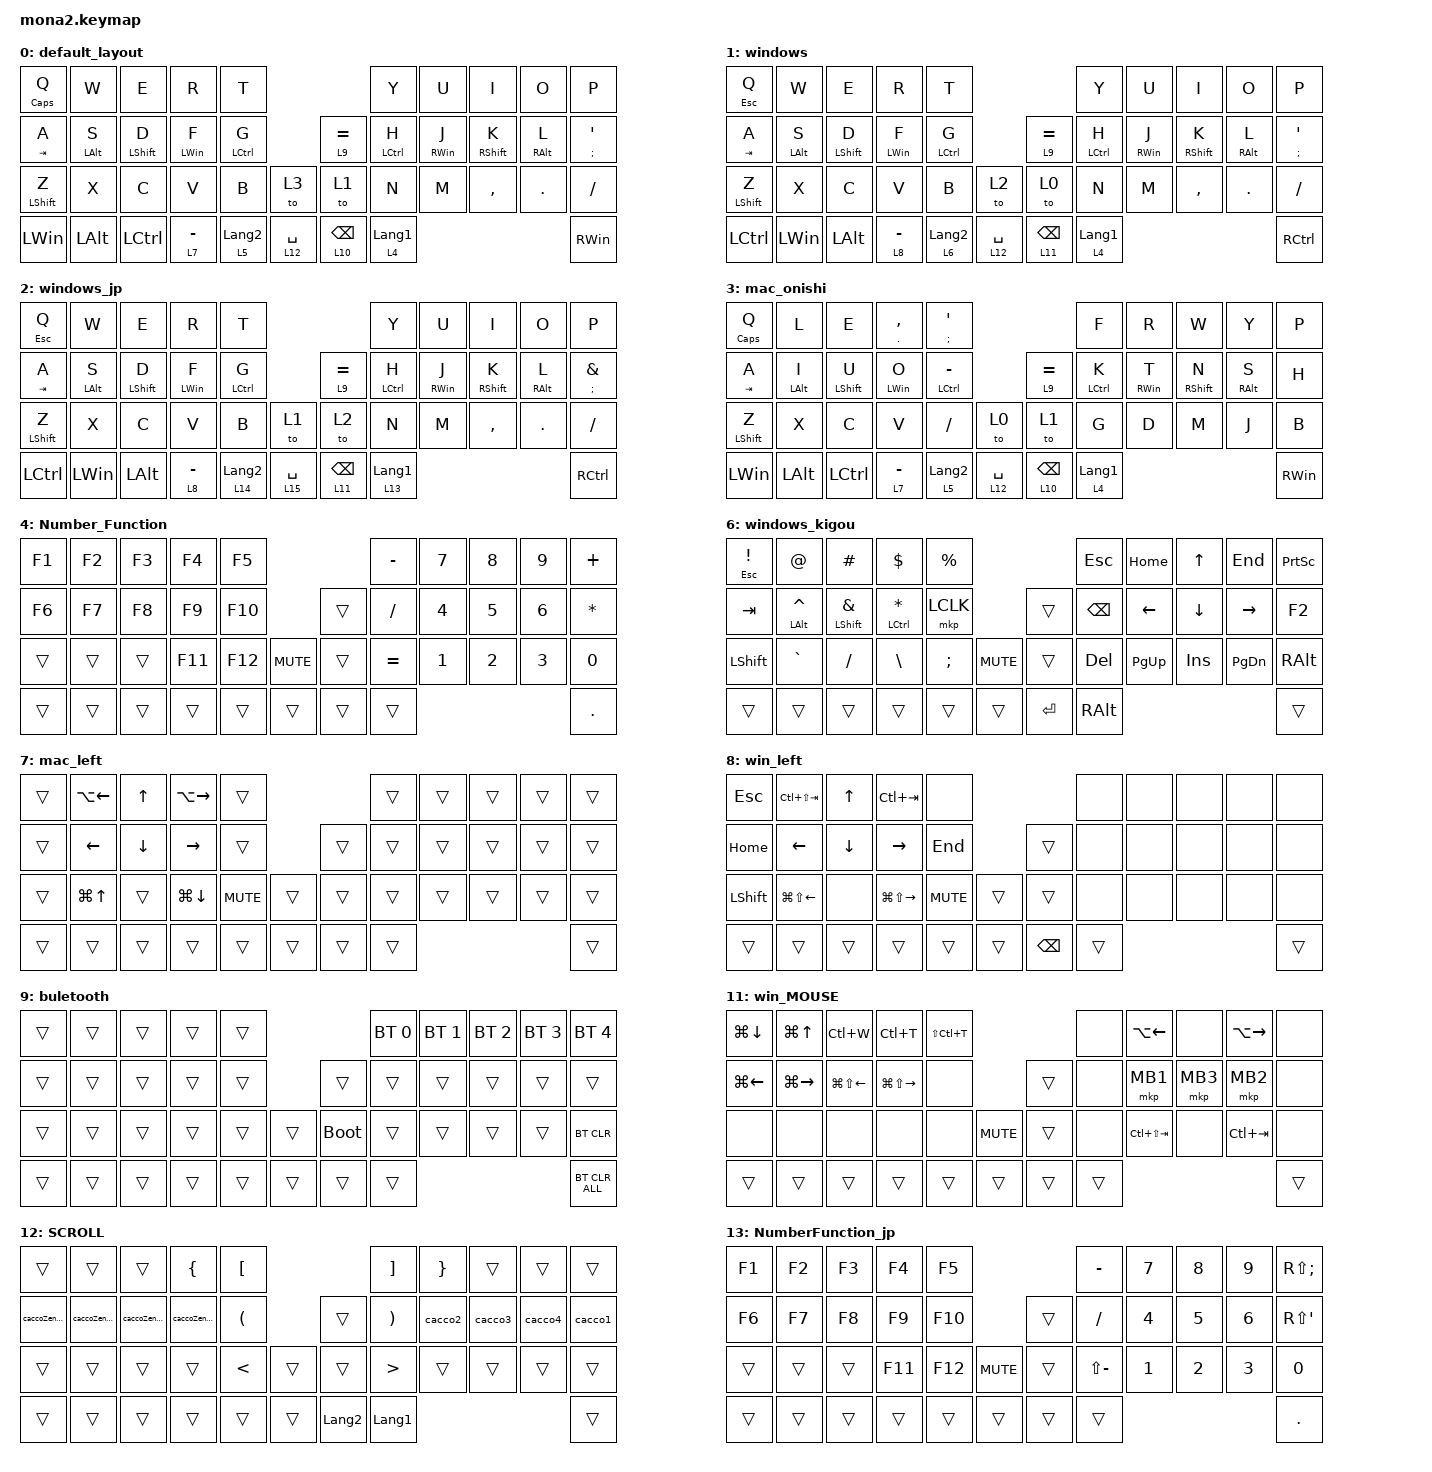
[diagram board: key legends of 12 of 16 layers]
#include <input/processors.dtsi>
#include <dt-bindings/zmk/input_transform.h>
#include <zephyr/dt-bindings/input/input-event-codes.h>
#include <behaviors.dtsi>
#include <dt-bindings/zmk/bt.h>
#include <dt-bindings/zmk/keys.h>
#include <dt-bindings/zmk/pointing.h>

#define ZMK_POINTING_DEFAULT_SCRL_VAL 100
#define MOUSE 5
#define SCROLL 12

&mt {
    flavor = "balanced";
    quick-tap-ms = <0>;
};

&lt {
    quick-tap-ms = <300>;
    flavor = "balanced";
};

/ {
    combos {
        compatible = "zmk,combos";

        layer4_ESC {
            bindings = <&lt 5 ESC>;
            key-positions = <39 38>;
        };

        tab {
            bindings = <&kp TAB>;
            key-positions = <11 12>;
        };
    };

    macros {
        to_layer_0: to_layer_0 {
            compatible = "zmk,behavior-macro-one-param";
            #binding-cells = <1>;
            bindings = <&to 1 &macro_param_1to1 &kp MACRO_PLACEHOLDER>;
            label = "TO_LAYER_0";
        };

        cacco1: cacco1 {
            compatible = "zmk,behavior-macro";
            #binding-cells = <0>;
            bindings = <&kp LANGUAGE_1 &kp LEFT_BRACE &kp RIGHT_BRACE &kp RET &kp LEFT_ARROW>;
            label = "CACCO1";
        };

        cacco2: cacco2 {
            compatible = "zmk,behavior-macro";
            #binding-cells = <0>;
            bindings = <&kp LANGUAGE_1 &kp LEFT_PARENTHESIS &kp RIGHT_PARENTHESIS &kp RETURN &kp LEFT>;
            label = "CACCO2";
        };

        cacco3: cacco3 {
            compatible = "zmk,behavior-macro";
            #binding-cells = <0>;
            bindings = <&kp LANGUAGE_1 &kp LEFT_BRACKET &kp RIGHT_BRACKET &kp RET &kp LEFT>;
            label = "CACCO3";
        };

        cacco4: cacco4 {
            compatible = "zmk,behavior-macro";
            #binding-cells = <0>;
            bindings = <&kp LANGUAGE_1 &kp LESS_THAN &kp GREATER_THAN &kp RET &kp LEFT_ARROW>;
            label = "CACCO4";
        };

        caccoZenkaku1: caccoZenkaku1 {
            compatible = "zmk,behavior-macro";
            #binding-cells = <0>;
            bindings = <&kp LANGUAGE_2 &kp LEFT_BRACE &kp RIGHT_BRACE &kp LEFT>;
            label = "CACCOZENKAKU1";
        };

        caccoZenkaku2: caccoZenkaku2 {
            compatible = "zmk,behavior-macro";
            #binding-cells = <0>;
            bindings = <&kp LANGUAGE_2 &kp LEFT_PARENTHESIS &kp RIGHT_PARENTHESIS &kp LEFT_ARROW>;
            label = "CACCOZENKAKU2";
        };

        caccoZenkaku3: caccoZenkaku3 {
            compatible = "zmk,behavior-macro";
            #binding-cells = <0>;
            bindings = <&kp LANGUAGE_2 &kp LEFT_BRACKET &kp RIGHT_BRACKET &kp LEFT>;
            label = "CACCOZENKAKU3";
        };

        caccoZenkaku4: caccoZenkaku4 {
            compatible = "zmk,behavior-macro";
            #binding-cells = <0>;
            bindings = <&kp LANGUAGE_2 &kp LESS_THAN &kp GREATER_THAN &kp LEFT>;
            label = "CACCOZENKAKU4";
        };

        cacco1JpHankaku: cacco1JpHankaku {
            compatible = "zmk,behavior-macro";
            #binding-cells = <0>;
            bindings = <&kp LANGUAGE_2 &kp RIGHT_BRACE &kp LS(BACKSLASH) &kp LEFT_ARROW>;
            label = "CACCO1JPHANKAKU";
        };

        cacco2JpHankaku: cacco2JpHankaku {
            compatible = "zmk,behavior-macro";
            #binding-cells = <0>;
            bindings = <&kp LANGUAGE_2 &kp ASTERISK &kp LEFT_PARENTHESIS &kp LEFT>;
            label = "CACCO2JPHANKAKU";
        };

        cacco3JpHankaku: cacco3JpHankaku {
            compatible = "zmk,behavior-macro";
            #binding-cells = <0>;
            bindings = <&kp LANGUAGE_2 &kp RIGHT_BRACKET &kp BACKSLASH &kp LEFT>;
            label = "CACCO3JPHANKAKU";
        };

        cacco4JpHankaku: cacco4JpHankaku {
            compatible = "zmk,behavior-macro";
            #binding-cells = <0>;
            bindings = <&kp LANGUAGE_2 &kp LESS_THAN &kp GREATER_THAN &kp LEFT>;
            label = "CACCO4JPHANKAKU";
        };

        cacco1JpZenkaku: cacco1JpZenkaku {
            compatible = "zmk,behavior-macro";
            #binding-cells = <0>;
            bindings = <&kp LANGUAGE_1 &kp RIGHT_BRACE &kp LS(BACKSLASH) &kp ENTER &kp LEFT>;
            label = "CACCO1JPZENKAKU";
        };

        cacco2JpZenkaku: cacco2JpZenkaku {
            compatible = "zmk,behavior-macro";
            #binding-cells = <0>;
            bindings = <&kp LANGUAGE_1 &kp ASTERISK &kp LEFT_PARENTHESIS &kp ENTER &kp LEFT_ARROW>;
            label = "CACCO2JPZENKAKU";
        };

        cacco3JpZenkaku: cacco3JpZenkaku {
            compatible = "zmk,behavior-macro";
            #binding-cells = <0>;
            bindings = <&kp LANGUAGE_1 &kp RIGHT_BRACKET &kp BACKSLASH &kp ENTER &kp LEFT>;
            label = "CACCO3JPZENKAKU";
        };

        cacco4JpZenkaku: cacco4JpZenkaku {
            compatible = "zmk,behavior-macro";
            #binding-cells = <0>;
            bindings = <&kp LANGUAGE_1 &kp LESS_THAN &kp GREATER_THAN &kp ENTER &kp LEFT>;
            label = "CACCO4JPZENKAKU";
        };

        jp_underbar: jp_underbar {
            compatible = "zmk,behavior-macro";
            #binding-cells = <0>;
            bindings =
                <&kp LANGUAGE_1 &kp L &kp I &kp A &kp ENTER>,
                <&macro_wait_time 1>,
                <&kp TAB>,
                <&macro_wait_time 1>,
                <&kp ENTER &kp LANGUAGE_2>;

            label = "JP_UNDERBAR";
            wait-ms = <5>;
        };

        jp_pipe: jp_pipe {
            compatible = "zmk,behavior-macro";
            #binding-cells = <0>;
            bindings =
                <&kp LANGUAGE_1 &kp L &kp A &kp I>,
                <&macro_wait_time 1>,
                <&kp TAB>,
                <&macro_wait_time 1>,
                <&kp ENTER &kp LANGUAGE_2>;

            label = "JP_PIPE";
            wait-ms = <5>;
        };

        jp_en: jp_en {
            compatible = "zmk,behavior-macro";
            #binding-cells = <0>;
            bindings =
                <&kp LANG_HANGEUL &kp L &kp U &kp A>,
                <&macro_wait_time 1>,
                <&kp TAB>,
                <&macro_wait_time 1>,
                <&kp ENTER &kp LANGUAGE_2>;

            label = "JP_EN";
            wait-ms = <5>;
        };
    };

    behaviors {
        lt_to_layer_0: lt_to_layer_0 {
            compatible = "zmk,behavior-hold-tap";
            label = "LAYER_TAP_TO_0";
            bindings = <&mo>, <&to_layer_0>;

            #binding-cells = <2>;
            tapping-term-ms = <200>;
        };

        scroll_up_down: mouse_wheel_up_down {
            compatible = "zmk,behavior-sensor-rotate";
            #sensor-binding-cells = <0>;
            bindings = <&msc SCRL_DOWN>, <&msc SCRL_UP>;

            tap-ms = <20>;
        };

        scroll_right_left: mouse_wheel_right_left {
            compatible = "zmk,behavior-sensor-rotate";
            #sensor-binding-cells = <0>;
            bindings = <&msc SCRL_LEFT>, <&msc SCRL_RIGHT>;

            tap-ms = <20>;
        };
    };

    keymap {
        compatible = "zmk,keymap";

        default_layout {
            bindings = <
&mt CAPSLOCK Q    &kp W           &kp E             &kp R           &kp T                                               &kp Y             &kp U            &kp I              &kp O            &kp P
&mt TAB A         &mt LEFT_ALT S  &mt LEFT_SHIFT D  &mt LEFT_WIN F  &mt LCTRL G                       &lt 9 EQUAL       &mt LCTRL H       &mt RIGHT_WIN J  &mt RIGHT_SHIFT K  &mt RIGHT_ALT L  &mt SEMICOLON SQT
&mt LEFT_SHIFT Z  &kp X           &kp C             &kp V           &kp B             &to 3           &to 1             &kp N             &kp M            &kp COMMA          &kp DOT          &kp SLASH
&kp LEFT_WIN      &kp LEFT_ALT    &kp LCTRL         &lt 7 MINUS     &lt 5 LANGUAGE_2  &lt 12 SPACE    &lt 10 BACKSPACE  &lt 4 LANGUAGE_1                                                       &kp RIGHT_WIN
            >;

            sensor-bindings = <&scroll_up_down>;
        };

        windows {
            bindings = <
&mt ESCAPE Q      &kp W           &kp E             &kp R           &kp T                                               &kp Y             &kp U            &kp I              &kp O            &kp P
&mt TAB A         &mt LEFT_ALT S  &mt LEFT_SHIFT D  &mt LEFT_WIN F  &mt LCTRL G                       &lt 9 EQUAL       &mt LCTRL H       &mt RIGHT_WIN J  &mt RIGHT_SHIFT K  &mt RIGHT_ALT L  &mt SEMICOLON SQT
&mt LEFT_SHIFT Z  &kp X           &kp C             &kp V           &kp B             &to 2           &to 0             &kp N             &kp M            &kp COMMA          &kp DOT          &kp SLASH
&kp LCTRL         &kp LEFT_WIN    &kp LEFT_ALT      &lt 8 MINUS     &lt 6 LANGUAGE_2  &lt 12 SPACE    &lt 11 BACKSPACE  &lt 4 LANGUAGE_1                                                       &kp RCTRL
            >;

            sensor-bindings = <&scroll_up_down>;
        };

        windows_jp {
            bindings = <
&mt ESCAPE Q      &kp W           &kp E             &kp R           &kp T                                                &kp Y              &kp U            &kp I              &kp O            &kp P
&mt TAB A         &mt LEFT_ALT S  &mt LEFT_SHIFT D  &mt LEFT_WIN F  &mt LCTRL G                        &lt 9 EQUAL       &mt LCTRL H        &mt RIGHT_WIN J  &mt RIGHT_SHIFT K  &mt RIGHT_ALT L  &mt SEMICOLON AMPERSAND
&mt LEFT_SHIFT Z  &kp X           &kp C             &kp V           &kp B              &to 1           &to 2             &kp N              &kp M            &kp COMMA          &kp DOT          &kp SLASH
&kp LCTRL         &kp LEFT_WIN    &kp LEFT_ALT      &lt 8 MINUS     &lt 14 LANGUAGE_2  &lt 15 SPACE    &lt 11 BACKSPACE  &lt 13 LANGUAGE_1                                                       &kp RCTRL
            >;

            sensor-bindings = <&scroll_up_down>;
        };

        mac_onishi {
            bindings = <
&mt CAPS Q        &kp L           &kp E             &mt PERIOD COMMA  &mt SEMICOLON SQT                                    &kp F             &kp R            &kp W              &kp Y            &kp P
&mt TAB A         &mt LEFT_ALT I  &mt LEFT_SHIFT U  &mt LEFT_WIN O    &mt LCTRL MINUS                    &lt 9 EQUAL       &mt LCTRL K       &mt RIGHT_WIN T  &mt RIGHT_SHIFT N  &mt RIGHT_ALT S  &kp H
&mt LEFT_SHIFT Z  &kp X           &kp C             &kp V             &kp SLASH          &to 0           &to 1             &kp G             &kp D            &kp M              &kp J            &kp B
&kp LEFT_WIN      &kp LEFT_ALT    &kp LCTRL         &lt 7 MINUS       &lt 5 LANGUAGE_2   &lt 12 SPACE    &lt 10 BACKSPACE  &lt 4 LANGUAGE_1                                                       &kp RIGHT_WIN
            >;

            sensor-bindings = <&scroll_up_down>;
        };

        Number_Function {
            bindings = <
&kp F1  &kp F2  &kp F3  &kp F4   &kp F5                         &kp MINUS  &kp N7        &kp N8        &kp N9        &kp PLUS
&kp F6  &kp F7  &kp F8  &kp F9   &kp F10                &trans  &kp SLASH  &kp NUMBER_4  &kp N5        &kp NUMBER_6  &kp ASTERISK
&trans  &trans  &trans  &kp F11  &kp F12  &kp C_MUTE    &trans  &kp EQUAL  &kp NUMBER_1  &kp NUMBER_2  &kp NUMBER_3  &kp N0
&trans  &trans  &trans  &trans   &trans   &trans        &trans  &trans                                               &kp PERIOD
            >;

            sensor-bindings = <&inc_dec_kp C_VOLUME_DOWN C_VOLUME_UP>;
        };

        mac_kigou {
            bindings = <
&mt ESCAPE EXCLAMATION  &kp AT_SIGN         &kp HASH                  &kp DOLLAR          &kp PERCENT                              &kp ESCAPE     &kp LG(LEFT)      &kp UP_ARROW  &kp LG(RIGHT)  &kp LC(LS(LG(NUMBER_4)))
&kp TAB                 &mt LEFT_ALT CARET  &mt LEFT_SHIFT AMPERSAND  &mt LCTRL ASTERISK  &mkp LCLK                    &trans      &kp BACKSPACE  &kp LEFT_ARROW    &kp DOWN      &kp RIGHT      &kp LC(U)
&kp LSHIFT              &kp GRAVE           &kp SLASH                 &kp BACKSLASH       &kp SEMICOLON  &kp C_MUTE    &trans      &kp DELETE     &kp LG(UP_ARROW)  &kp INS       &kp LG(DOWN)   &kp RIGHT_ALT
&trans                  &trans              &trans                    &trans              &trans         &trans        &kp RETURN  &kp RIGHT_ALT                                                 &kp LS(LG(NUMBER_3))
            >;

            sensor-bindings = <&inc_dec_kp F14 F15>;
        };

        windows_kigou {
            bindings = <
&mt ESCAPE EXCLAMATION  &kp AT_SIGN         &kp HASH                  &kp DOLLAR          &kp PERCENT                              &kp ESCAPE     &kp HOME        &kp UP_ARROW  &kp END        &kp PRINTSCREEN
&kp TAB                 &mt LEFT_ALT CARET  &mt LEFT_SHIFT AMPERSAND  &mt LCTRL ASTERISK  &mkp LCLK                    &trans      &kp BACKSPACE  &kp LEFT_ARROW  &kp DOWN      &kp RIGHT      &kp F2
&kp LSHIFT              &kp GRAVE           &kp SLASH                 &kp BACKSLASH       &kp SEMICOLON  &kp C_MUTE    &trans      &kp DELETE     &kp PAGE_UP     &kp INS       &kp PAGE_DOWN  &kp RIGHT_ALT
&trans                  &trans              &trans                    &trans              &trans         &trans        &kp RETURN  &kp RIGHT_ALT                                               &trans
            >;

            sensor-bindings = <&inc_dec_kp PAGE_DOWN PAGE_UP>;
        };

        mac_left {
            bindings = <
&trans  &kp LA(LEFT_ARROW)  &kp UP_ARROW  &kp LA(RIGHT)  &trans                        &trans  &trans  &trans  &trans  &trans
&trans  &kp LEFT_ARROW      &kp DOWN      &kp RIGHT      &trans                &trans  &trans  &trans  &trans  &trans  &trans
&trans  &kp LG(UP_ARROW)    &trans        &kp LG(DOWN)   &kp C_MUTE  &trans    &trans  &trans  &trans  &trans  &trans  &trans
&trans  &trans              &trans        &trans         &trans      &trans    &trans  &trans                          &trans
            >;

            sensor-bindings = <&inc_dec_kp F15 F14>;
        };

        win_left {
            bindings = <
&kp ESCAPE      &kp LC(LS(TAB))         &kp UP_ARROW    &kp LC(TAB)              &none                                &none   &none  &none  &none  &none
&kp HOME        &kp LEFT_ARROW          &kp DOWN_ARROW  &kp RIGHT_ARROW          &kp END               &trans         &none   &none  &none  &none  &none
&kp LEFT_SHIFT  &kp LG(LS(LEFT_ARROW))  &none           &kp LG(LS(RIGHT_ARROW))  &kp C_MUTE  &trans    &trans         &none   &none  &none  &none  &none
&trans          &trans                  &trans          &trans                   &trans      &trans    &kp BACKSPACE  &trans                       &trans
            >;

            sensor-bindings = <&inc_dec_kp C_VOLUME_DOWN C_VOLUME_UP>;
        };

        buletooth {
            bindings = <
&trans  &trans  &trans  &trans  &trans                         &bt BT_SEL 0  &bt BT_SEL 1  &bt BT_SEL 2  &bt BT_SEL 3  &bt BT_SEL 4
&trans  &trans  &trans  &trans  &trans            &trans       &trans        &trans        &trans        &trans        &trans
&trans  &trans  &trans  &trans  &trans  &trans    &bootloader  &trans        &trans        &trans        &trans        &bt BT_CLR
&trans  &trans  &trans  &trans  &trans  &trans    &trans       &trans                                                  &bt BT_CLR_ALL
            >;

            sensor-bindings = <&scroll_up_down>;
        };

        mac_Mouse {
            bindings = <
&kp LG(LC(LA(M)))  &kp LG(LA(LC(LEFT)))  &kp LC(LG(UP_ARROW))  &kp LA(LC(LG(UP_ARROW)))  &kp LG(BACKSLASH)                    &trans  &kp LG(LEFT_BRACKET)  &trans    &kp LG(RIGHT_BRACKET)  &trans
&kp LC(UP_ARROW)   &kp LG(LC(LEFT))      &kp LG(LC(DOWN))      &kp LG(LC(RIGHT))         &kp LG(RC(RS(D)))            &trans  &trans  &mkp MB1              &mkp MB3  &mkp MB2               &trans
&kp LC(DOWN)       &kp LC(LG(LA(DOWN)))  &trans                &kp LC(LG(LA(RIGHT)))     &trans             &trans    &trans  &trans  &kp LC(LS(TAB))       &trans    &kp LC(TAB)            &trans
&trans             &trans                &trans                &trans                    &trans             &trans    &trans  &trans                                                         &trans
            >;

            sensor-bindings = <&inc_dec_kp F14 F15>;
        };

        win_MOUSE {
            bindings = <
&kp LG(DOWN)  &kp LG(UP_ARROW)  &kp LC(W)         &kp LC(T)          &kp LS(LC(T))                        &none   &kp LA(LEFT)     &none     &kp LA(RIGHT)  &none
&kp LG(LEFT)  &kp LG(RIGHT)     &kp LG(LS(LEFT))  &kp LG(LS(RIGHT))  &none                        &trans  &none   &mkp MB1         &mkp MB3  &mkp MB2       &none
&none         &none             &none             &none              &none          &kp C_MUTE    &trans  &none   &kp LC(LS(TAB))  &none     &kp LC(TAB)    &none
&trans        &trans            &trans            &trans             &trans         &trans        &trans  &trans                                            &trans
            >;

            sensor-bindings = <&inc_dec_kp DOWN_ARROW UP>;
        };

        SCROLL {
            bindings = <
&trans          &trans          &trans          &kp LEFT_BRACE  &kp LEFT_BRACKET                                &kp RIGHT_BRACKET      &kp RIGHT_BRACE  &trans   &trans   &trans
&caccoZenkaku1  &caccoZenkaku4  &caccoZenkaku3  &caccoZenkaku2  &kp LEFT_PARENTHESIS            &trans          &kp RIGHT_PARENTHESIS  &cacco2          &cacco3  &cacco4  &cacco1
&trans          &trans          &trans          &trans          &kp LESS_THAN         &trans    &trans          &kp GREATER_THAN       &trans           &trans   &trans   &trans
&trans          &trans          &trans          &trans          &trans                &trans    &kp LANGUAGE_2  &kp LANGUAGE_1                                            &trans
            >;

            sensor-bindings = <&inc_dec_kp LA(TAB) LA(LS(TAB))>;
        };

        NumberFunction_jp {
            bindings = <
&kp F1  &kp F2  &kp F3  &kp F4   &kp F5                         &kp MINUS      &kp N7        &kp N8        &kp N9        &kp RS(SEMICOLON)
&kp F6  &kp F7  &kp F8  &kp F9   &kp F10                &trans  &kp SLASH      &kp NUMBER_4  &kp N5        &kp NUMBER_6  &kp RS(SINGLE_QUOTE)
&trans  &trans  &trans  &kp F11  &kp F12  &kp C_MUTE    &trans  &kp LS(MINUS)  &kp NUMBER_1  &kp NUMBER_2  &kp NUMBER_3  &kp N0
&trans  &trans  &trans  &trans   &trans   &trans        &trans  &trans                                                   &kp PERIOD
            >;

            sensor-bindings = <&inc_dec_kp C_VOLUME_DOWN C_VOLUME_UP>;
        };

        win_jp_kigou {
            bindings = <
&kp EXCLAMATION  &kp LEFT_BRACKET  &kp HASH   &kp DOLLAR            &kp PERCENT                                      &kp ESC        &kp HOME     &kp UP_ARROW    &kp END        &kp PRINTSCREEN
&kp TAB          &kp EQUAL         &kp CARET  &kp RS(SINGLE_QUOTE)  &mkp LCLK                             &trans     &kp BACKSPACE  &kp LEFT     &kp DOWN_ARROW  &kp RIGHT      &kp F2
&kp LSHIFT       &jp_underbar      &jp_pipe   &jp_en                &mt SEMICOLON SINGLE_QUOTE  &trans    &trans     &kp DELETE     &kp PAGE_UP  &kp INS         &kp PAGE_DOWN  &kp RIGHT_ALT
&kp LCTRL        &kp LEFT_WIN      &trans     &trans                &trans                      &trans    &kp ENTER  &kp LEFT_ALT                                               &trans
            >;
        };

        windows_jp_kakko {
            bindings = <
&trans            &trans            &trans            &kp RBRC          &kp RIGHT_BRACKET                    &kp BACKSLASH         &kp LS(BACKSLASH)  &trans            &trans            &trans
&cacco1JpHankaku  &cacco4JpHankaku  &cacco3JpHankaku  &cacco2JpHankaku  &kp ASTERISK                 &trans  &kp LEFT_PARENTHESIS  &cacco2JpZenkaku   &cacco3JpZenkaku  &cacco4JpZenkaku  &cacco1JpZenkaku
&trans            &trans            &trans            &trans            &kp LESS_THAN      &trans    &trans  &kp GREATER_THAN      &trans             &trans            &trans            &trans
&trans            &trans            &trans            &trans            &trans             &trans    &trans  &trans                                                                       &trans
            >;
        };
    };
};
